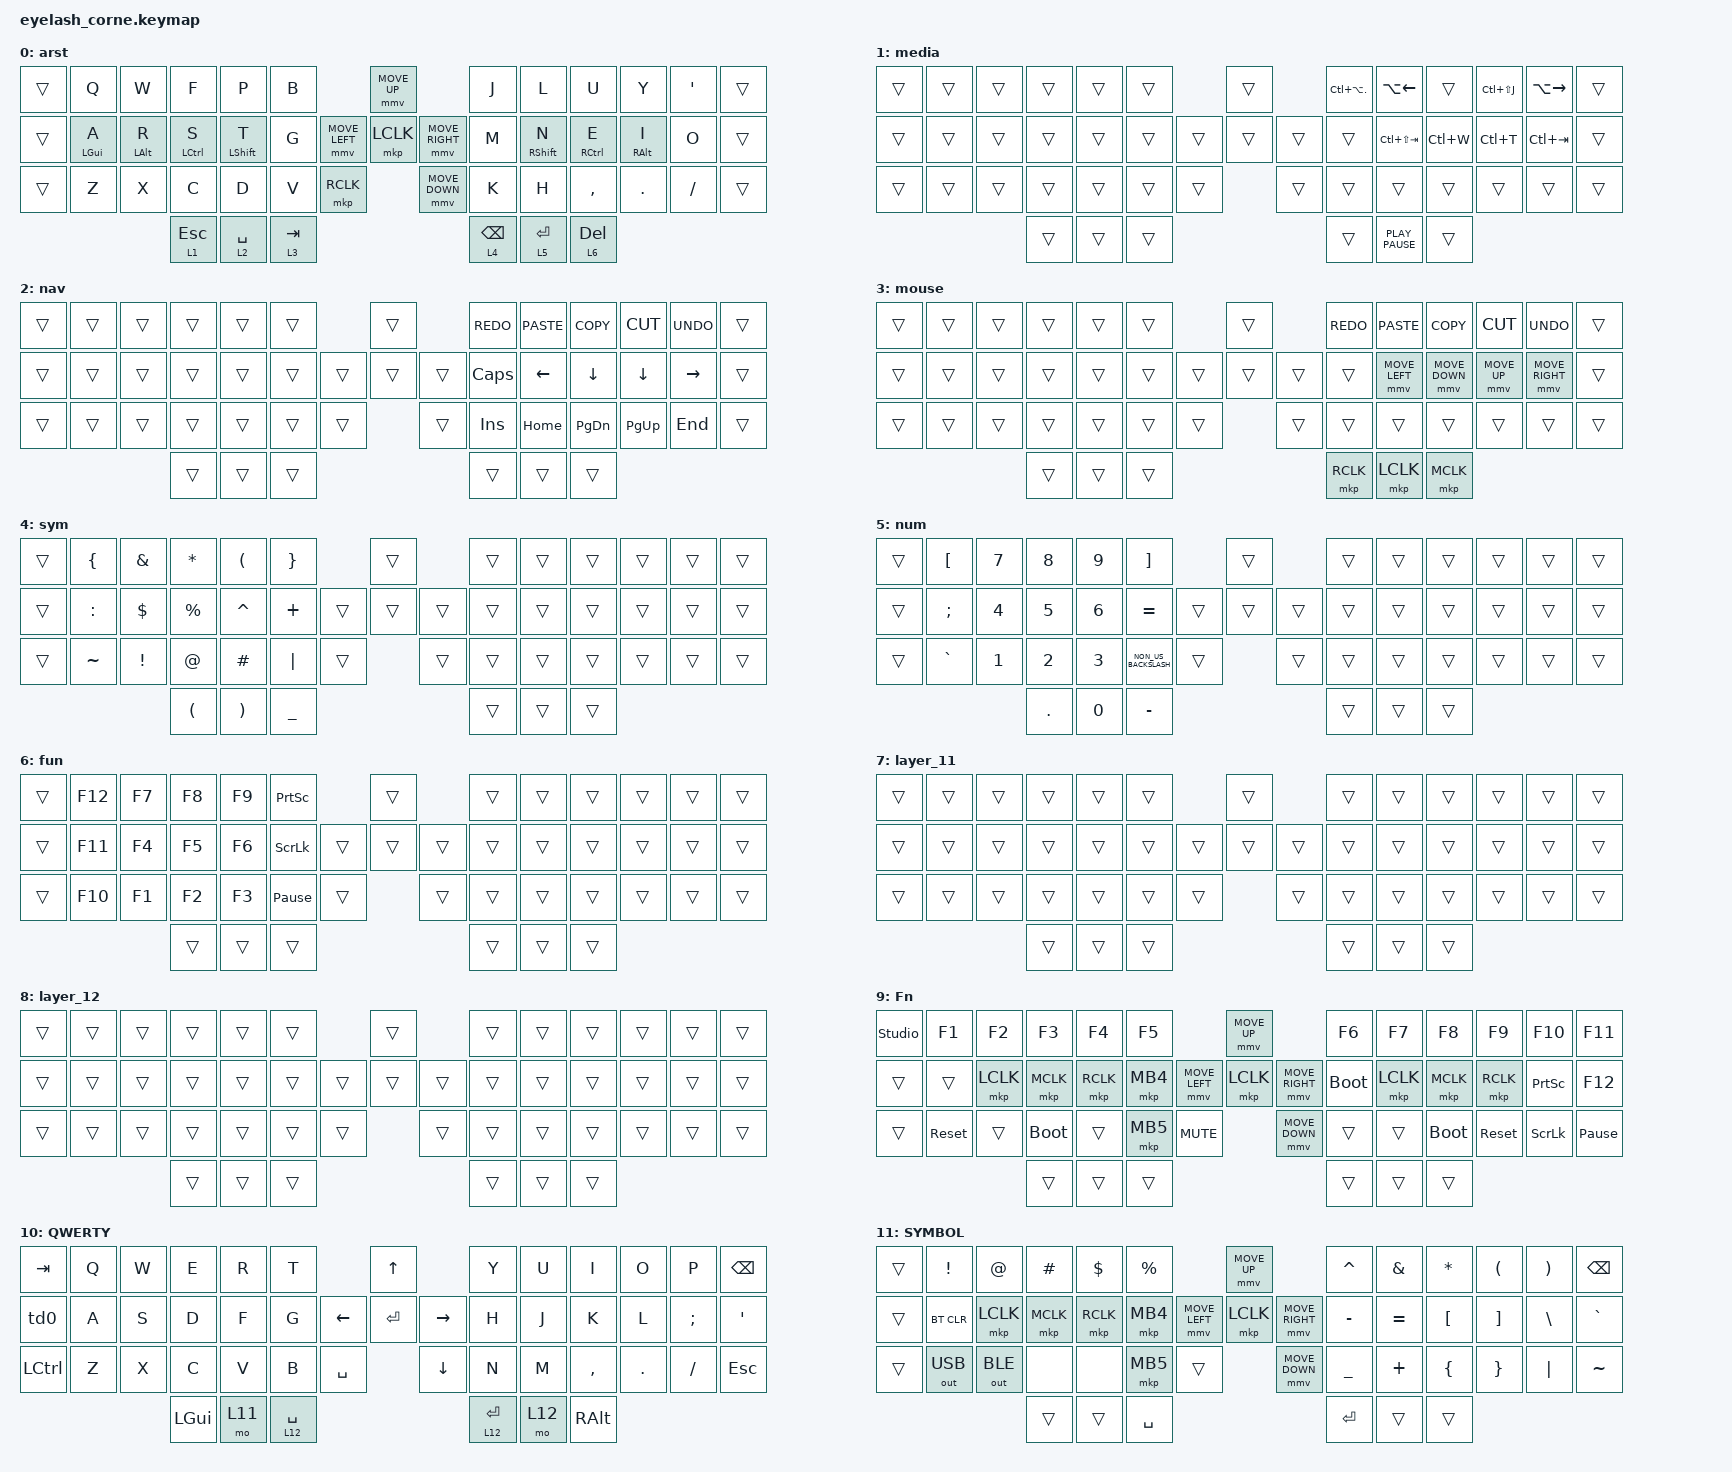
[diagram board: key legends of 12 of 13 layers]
#define ZMK_POINTING_DEFAULT_MOVE_VAL 1200  // 600
#define ZMK_POINTING_DEFAULT_SCRL_VAL 25   // 10

#include <input/processors.dtsi>
#include <zephyr/dt-bindings/input/input-event-codes.h>
#include <behaviors.dtsi>
#include <dt-bindings/zmk/bt.h>
#include <dt-bindings/zmk/keys.h>
#include <dt-bindings/zmk/outputs.h>
#include <dt-bindings/zmk/pointing.h>
#include <dt-bindings/zmk/rgb.h>

&mmv_input_listener { input-processors = <&zip_xy_scaler 2 1>; };

&msc_input_listener { input-processors = <&zip_scroll_scaler 2 1>; };

&msc {
    acceleration-exponent = <1>;      // 0
    time-to-max-speed-ms = <100>;       // 300
    delay-ms = <0>;                   // 0
};

&mmv {
    time-to-max-speed-ms = <500>;
    acceleration-exponent = <1>;
    trigger-period-ms = <16>;
};

&soft_off { hold-time-ms = <2000>; };

/ {
    behaviors {
        td0: td0 {
            compatible = "zmk,behavior-tap-dance";
            display-name = "Shift/Caps Lock Tap Dance";
            #binding-cells = <0>;
            bindings = <&kp LEFT_SHIFT>, <&kp CAPS>;
        };
    };

    rgb_encoder: rgb_encoder {
        compatible = "zmk,behavior-sensor-rotate";
        #sensor-binding-cells = <0>;
        bindings = <&rgb_ug RGB_BRI>, <&rgb_ug RGB_BRD>;
    };

    scroll_encoder: scroll_encoder {
        compatible = "zmk,behavior-sensor-rotate";
        #sensor-binding-cells = <0>;
        bindings = <&msc SCRL_DOWN>, <&msc SCRL_UP>;

        tap-ms = <100>;
    };

    combos {
        compatible = "zmk,combos";

        softoff {
            bindings = <&soft_off>;
            key-positions = <1 15 29>;
        };
    };

    keymap {
        compatible = "zmk,keymap";

        default_layer {
            bindings = <
&trans  &kp Q           &kp W           &kp F        &kp P             &kp B                                   &mmv MOVE_UP                     &kp J            &kp L              &kp U         &kp Y            &kp SQT    &trans
&trans  &mt LEFT_GUI A  &mt LEFT_ALT R  &mt LCTRL S  &mt LEFT_SHIFT T  &kp G                   &mmv MOVE_LEFT  &mkp LCLK       &mmv MOVE_RIGHT  &kp M            &mt RIGHT_SHIFT N  &mt RCTRL E   &mt RIGHT_ALT I  &kp O      &trans
&trans  &kp Z           &kp X           &kp C        &kp D             &kp V      &mkp RCLK                    &mmv MOVE_DOWN                   &kp K            &kp H              &kp COMMA     &kp PERIOD       &kp SLASH  &trans
                                        &lt 1 ESC    &lt 2 SPACE       &lt 3 TAB                                                                &lt 4 BACKSPACE  &lt 5 ENTER        &lt 6 DELETE
            >;

            sensor-bindings = <&inc_dec_kp C_VOL_UP C_VOLUME_DOWN>;
            label = "arst";
        };

        media {
            bindings = <
&trans  &trans  &trans  &trans  &trans  &trans                    &trans          &kp LC(LA(PERIOD))  &kp LA(LEFT)      &trans     &kp LC(LS(J))  &kp LA(RIGHT)  &trans
&trans  &trans  &trans  &trans  &trans  &trans            &trans  &trans  &trans  &trans              &kp LC(LS(TAB))   &kp LC(W)  &kp LC(T)      &kp LC(TAB)    &trans
&trans  &trans  &trans  &trans  &trans  &trans  &trans            &trans          &trans              &trans            &trans     &trans         &trans         &trans
                        &trans  &trans  &trans                                    &trans              &kp K_PLAY_PAUSE  &trans
            >;

            sensor-bindings = <&inc_dec_kp C_VOL_UP C_VOLUME_DOWN>;
        };

        nav {
            bindings = <
&trans  &trans  &trans  &trans  &trans  &trans                    &trans          &kp K_REDO  &kp K_PASTE  &kp K_COPY     &kp K_CUT    &kp K_UNDO  &trans
&trans  &trans  &trans  &trans  &trans  &trans            &trans  &trans  &trans  &kp CAPS    &kp LEFT     &kp DOWN       &kp DOWN     &kp RIGHT   &trans
&trans  &trans  &trans  &trans  &trans  &trans  &trans            &trans          &kp INSERT  &kp HOME     &kp PAGE_DOWN  &kp PAGE_UP  &kp END     &trans
                        &trans  &trans  &trans                                    &trans      &trans       &trans
            >;

            sensor-bindings = <&inc_dec_kp C_VOL_UP C_VOLUME_DOWN>;
        };

        mouse {
            bindings = <
&trans  &trans  &trans  &trans  &trans  &trans                    &trans          &kp K_REDO  &kp K_PASTE     &kp K_COPY      &kp K_CUT     &kp K_UNDO       &trans
&trans  &trans  &trans  &trans  &trans  &trans            &trans  &trans  &trans  &trans      &mmv MOVE_LEFT  &mmv MOVE_DOWN  &mmv MOVE_UP  &mmv MOVE_RIGHT  &trans
&trans  &trans  &trans  &trans  &trans  &trans  &trans            &trans          &trans      &trans          &trans          &trans        &trans           &trans
                        &trans  &trans  &trans                                    &mkp RCLK   &mkp LCLK       &mkp MCLK
            >;

            sensor-bindings = <&inc_dec_kp C_VOL_UP C_VOLUME_DOWN>;
        };

        sym {
            bindings = <
&trans  &kp LEFT_BRACE  &kp AMPERSAND    &kp ASTERISK          &kp LEFT_PARENTHESIS   &kp RIGHT_BRACE                    &trans          &trans  &trans  &trans  &trans  &trans  &trans
&trans  &kp COLON       &kp DOLLAR       &kp PERCENT           &kp CARET              &kp PLUS                   &trans  &trans  &trans  &trans  &trans  &trans  &trans  &trans  &trans
&trans  &kp TILDE       &kp EXCLAMATION  &kp AT_SIGN           &kp HASH               &kp PIPE         &trans            &trans          &trans  &trans  &trans  &trans  &trans  &trans
                                         &kp LEFT_PARENTHESIS  &kp RIGHT_PARENTHESIS  &kp UNDERSCORE                                     &trans  &trans  &trans
            >;

            sensor-bindings = <&inc_dec_kp C_VOL_UP C_VOLUME_DOWN>;
        };

        num {
            bindings = <
&trans  &kp LEFT_BRACKET  &kp NUMBER_7  &kp NUMBER_8  &kp NUMBER_9  &kp RIGHT_BRACKET                       &trans          &trans  &trans  &trans  &trans  &trans  &trans
&trans  &kp SEMICOLON     &kp NUMBER_4  &kp NUMBER_5  &kp NUMBER_6  &kp EQUAL                       &trans  &trans  &trans  &trans  &trans  &trans  &trans  &trans  &trans
&trans  &kp GRAVE         &kp NUMBER_1  &kp NUMBER_2  &kp NUMBER_3  &kp NON_US_BACKSLASH  &trans            &trans          &trans  &trans  &trans  &trans  &trans  &trans
                                        &kp PERIOD    &kp NUMBER_0  &kp MINUS                                               &trans  &trans  &trans
            >;
        };

        fun {
            bindings = <
&trans  &kp F12  &kp F7  &kp F8  &kp F9  &kp PRINTSCREEN                    &trans          &trans  &trans  &trans  &trans  &trans  &trans
&trans  &kp F11  &kp F4  &kp F5  &kp F6  &kp SCROLLLOCK             &trans  &trans  &trans  &trans  &trans  &trans  &trans  &trans  &trans
&trans  &kp F10  &kp F1  &kp F2  &kp F3  &kp PAUSE_BREAK  &trans            &trans          &trans  &trans  &trans  &trans  &trans  &trans
                         &trans  &trans  &trans                                             &trans  &trans  &trans
            >;
        };

        layer_11 {
            bindings = <
&trans  &trans  &trans  &trans  &trans  &trans                    &trans          &trans  &trans  &trans  &trans  &trans  &trans
&trans  &trans  &trans  &trans  &trans  &trans            &trans  &trans  &trans  &trans  &trans  &trans  &trans  &trans  &trans
&trans  &trans  &trans  &trans  &trans  &trans  &trans            &trans          &trans  &trans  &trans  &trans  &trans  &trans
                        &trans  &trans  &trans                                    &trans  &trans  &trans
            >;
        };

        layer_12 {
            bindings = <
&trans  &trans  &trans  &trans  &trans  &trans                    &trans          &trans  &trans  &trans  &trans  &trans  &trans
&trans  &trans  &trans  &trans  &trans  &trans            &trans  &trans  &trans  &trans  &trans  &trans  &trans  &trans  &trans
&trans  &trans  &trans  &trans  &trans  &trans  &trans            &trans          &trans  &trans  &trans  &trans  &trans  &trans
                        &trans  &trans  &trans                                    &trans  &trans  &trans
            >;
        };

        layer_3 {
            display-name = "Fn";
            bindings = <
&studio_unlock  &kp F1      &kp F2     &kp F3       &kp F4     &kp F5                                  &mmv MOVE_UP                     &kp F6       &kp F7     &kp F8       &kp F9      &kp F10          &kp F11
&trans          &trans      &mkp LCLK  &mkp MCLK    &mkp RCLK  &mkp MB4                &mmv MOVE_LEFT  &mkp LCLK       &mmv MOVE_RIGHT  &bootloader  &mkp LCLK  &mkp MCLK    &mkp RCLK   &kp PRINTSCREEN  &kp F12
&trans          &sys_reset  &trans     &bootloader  &trans     &mkp MB5  &kp C_MUTE                    &mmv MOVE_DOWN                   &trans       &trans     &bootloader  &sys_reset  &kp SCROLLLOCK   &kp PAUSE_BREAK
                                       &trans       &trans     &trans                                                                   &trans       &trans     &trans
            >;

            sensor-bindings = <&scroll_encoder>;
        };

        default_layerr {
            display-name = "QWERTY";
            bindings = <
&kp TAB    &kp Q  &kp W  &kp E     &kp R   &kp T                                &kp UP                &kp Y         &kp U   &kp I      &kp O    &kp P     &kp BSPC
&td0       &kp A  &kp S  &kp D     &kp F   &kp G                      &kp LEFT  &kp ENTER  &kp RIGHT  &kp H         &kp J   &kp K      &kp L    &kp SEMI  &kp SQT
&kp LCTRL  &kp Z  &kp X  &kp C     &kp V   &kp B         &kp SPACE              &kp DOWN              &kp N         &kp M   &kp COMMA  &kp DOT  &kp FSLH  &kp ESC
                         &kp LGUI  &mo 11  &lt 12 SPACE                                               &lt 12 ENTER  &mo 12  &kp RALT
            >;

            sensor-bindings = <&inc_dec_kp C_VOLUME_UP C_VOLUME_DOWN>;
        };

        raise_layer {
            display-name = "SYMBOL";
            bindings = <
&trans  &kp EXCL      &kp AT        &kp HASH   &kp DLLR   &kp PRCNT                            &mmv MOVE_UP                     &kp CARET  &kp AMPS   &kp ASTRK  &kp LPAR  &kp RPAR  &kp BSPC
&trans  &bt BT_CLR    &mkp LCLK     &mkp MCLK  &mkp RCLK  &mkp MB4             &mmv MOVE_LEFT  &mkp LCLK       &mmv MOVE_RIGHT  &kp MINUS  &kp EQUAL  &kp LBKT   &kp RBKT  &kp BSLH  &kp GRAVE
&trans  &out OUT_USB  &out OUT_BLE  &none      &none      &mkp MB5   &trans                    &mmv MOVE_DOWN                   &kp UNDER  &kp PLUS   &kp LBRC   &kp RBRC  &kp PIPE  &kp TILDE
                                    &trans     &trans     &kp SPACE                                                             &kp RET    &trans     &trans
            >;

            sensor-bindings = <&scroll_encoder>;
        };

        lower_layer {
            display-name = "NUMBER";
            bindings = <
&trans  &kp N1           &kp N2          &kp N3        &kp N4        &kp N5                                         &mmv MOVE_UP                     &kp N6           &kp N7           &kp N8           &kp N9           &kp N0    &kp BSPC
&trans  &bt BT_CLR_ALL   &bt BT_SEL 0    &bt BT_SEL 1  &bt BT_SEL 2  &bt BT_SEL 3                   &mmv MOVE_LEFT  &mkp LCLK       &mmv MOVE_RIGHT  &kp LEFT         &kp DOWN         &kp UP           &kp RIGHT        &kp HOME  &kp PG_UP
&trans  &rgb_ug RGB_OFF  &rgb_ug RGB_ON  &trans        &trans        &rgb_ug RGB_EFF  &kp C_MUTE                    &mmv MOVE_DOWN                   &rgb_ug RGB_EFR  &rgb_ug RGB_SPI  &rgb_ug RGB_BRI  &rgb_ug RGB_BRD  &kp END   &kp PG_DN
                                         &trans        &trans        &trans                                                                          &kp INS          &kp DEL          &trans
            >;

            sensor-bindings = <&scroll_encoder>;
        };
    };
};
